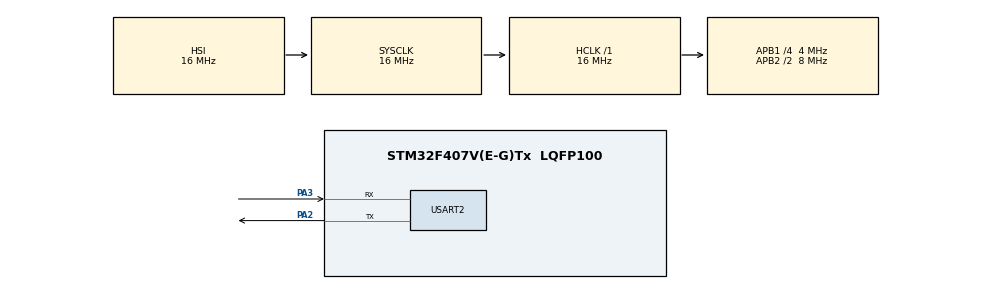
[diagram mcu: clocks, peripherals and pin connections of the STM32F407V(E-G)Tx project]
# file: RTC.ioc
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Mcu.Family=STM32F4
Mcu.Name=STM32F407V(E-G)Tx
Mcu.Package=LQFP100
NVIC.PriorityGroup=NVIC_PRIORITYGROUP_0
NVIC.USART2_IRQn=true\:0\:0\:false\:false\:true\:true\:true\:true
PA2.Mode=Asynchronous
PA2.Signal=USART2_TX
PA3.Mode=Asynchronous
PA3.Signal=USART2_RX
ProjectManager.HeapSize=0x200
ProjectManager.StackSize=0x400
ProjectManager.TargetToolchain=STM32CubeIDE
RCC.48MHZClocksFreq_Value=14285714.285714285
RCC.AHBFreq_Value=16000000
RCC.APB1CLKDivider=RCC_HCLK_DIV4
RCC.APB1Freq_Value=4000000
RCC.APB1TimFreq_Value=8000000
RCC.APB2CLKDivider=RCC_HCLK_DIV2
RCC.APB2Freq_Value=8000000
RCC.APB2TimFreq_Value=16000000
RCC.CortexFreq_Value=16000000
RCC.HCLKFreq_Value=16000000
RCC.HSE_VALUE=8000000
RCC.HSI_VALUE=16000000
RCC.LSE_VALUE=32768
RCC.PLLM=8
RCC.PLLN=50
RCC.PLLP=RCC_PLLP_DIV4
RCC.PLLQ=7
RCC.SYSCLKFreq_VALUE=16000000
RCC.VCOOutputFreq_Value=100000000
USART2.VirtualMode=VM_ASYNC
VP_RTC_VS_RTC_Activate.Mode=RTC_Enabled
VP_RTC_VS_RTC_Calendar.Mode=RTC_Calendar
board=STM32F407G-DISC1

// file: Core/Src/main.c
/* USER CODE BEGIN Header */
/**
  ******************************************************************************
  * @file           : main.c
  * @brief          : Main program body
  ******************************************************************************
  * @attention
  *
  * Copyright (c) 2025 STMicroelectronics.
  * All rights reserved.
  *
  * This software is licensed under terms that can be found in the LICENSE file
  * in the root directory of this software component.
  * If no LICENSE file comes with this software, it is provided AS-IS.
  *
  ******************************************************************************
  */
/* USER CODE END Header */
#include "main.h"

/* USER CODE BEGIN Includes */
#include "stm32f4xx_hal.h"
#include<stdio.h>
#include <string.h>

/* USER CODE END Includes */

RTC_HandleTypeDef hrtc;

UART_HandleTypeDef huart2;

/* USER CODE BEGIN PV */
int __io_putchar(int ch) {
    HAL_UART_Transmit(&huart2, (uint8_t *)&ch, 1, HAL_MAX_DELAY);
    return ch;
}

/* USER CODE END PV */

void SystemClock_Config(void);
static void MX_GPIO_Init(void);
static void MX_RTC_Init(void);
static void MX_USART2_UART_Init(void);

int main(void)
{

  /* MCU Configuration--------------------------------------------------------*/

  /* Reset of all peripherals, Initializes the Flash interface and the Systick. */
  HAL_Init();

  /* Configure the system clock */
  SystemClock_Config();

  /* Initialize all configured peripherals */
  MX_GPIO_Init();
  MX_RTC_Init();
  MX_USART2_UART_Init();
  /* USER CODE BEGIN 2 */

  RTC_TimeTypeDef sTime;
  RTC_DateTypeDef sDate;

  /* USER CODE END 2 */

  /* Infinite loop */
  while (1)
  {
	  HAL_RTC_GetTime(&hrtc, &sTime, RTC_FORMAT_BIN);
	          HAL_RTC_GetDate(&hrtc, &sDate, RTC_FORMAT_BIN);

	          printf("%02d:%02d:%02d\r\n", sTime.Hours, sTime.Minutes, sTime.Seconds);

	          HAL_Delay(1000);

  }
}

void SystemClock_Config(void)
{
  RCC_OscInitTypeDef RCC_OscInitStruct = {0};
  RCC_ClkInitTypeDef RCC_ClkInitStruct = {0};

  /** Configure the main internal regulator output voltage
  */
  __HAL_RCC_PWR_CLK_ENABLE();
  __HAL_PWR_VOLTAGESCALING_CONFIG(PWR_REGULATOR_VOLTAGE_SCALE1);

  /** Initializes the RCC Oscillators according to the specified parameters
  * in the RCC_OscInitTypeDef structure.
  */
  RCC_OscInitStruct.OscillatorType = RCC_OSCILLATORTYPE_HSI|RCC_OSCILLATORTYPE_LSI;
  RCC_OscInitStruct.HSIState = RCC_HSI_ON;
  RCC_OscInitStruct.HSICalibrationValue = RCC_HSICALIBRATION_DEFAULT;
  RCC_OscInitStruct.LSIState = RCC_LSI_ON;
  RCC_OscInitStruct.PLL.PLLState = RCC_PLL_NONE;
  if (HAL_RCC_OscConfig(&RCC_OscInitStruct) != HAL_OK)
  {
    Error_Handler();
  }

  /** Initializes the CPU, AHB and APB buses clocks
  */
  RCC_ClkInitStruct.ClockType = RCC_CLOCKTYPE_HCLK|RCC_CLOCKTYPE_SYSCLK
                              |RCC_CLOCKTYPE_PCLK1|RCC_CLOCKTYPE_PCLK2;
  RCC_ClkInitStruct.SYSCLKSource = RCC_SYSCLKSOURCE_HSI;
  RCC_ClkInitStruct.AHBCLKDivider = RCC_SYSCLK_DIV1;
  RCC_ClkInitStruct.APB1CLKDivider = RCC_HCLK_DIV4;
  RCC_ClkInitStruct.APB2CLKDivider = RCC_HCLK_DIV2;

  if (HAL_RCC_ClockConfig(&RCC_ClkInitStruct, FLASH_LATENCY_0) != HAL_OK)
  {
    Error_Handler();
  }
}

static void MX_RTC_Init(void)
{

  RTC_TimeTypeDef sTime = {0};
  RTC_DateTypeDef sDate = {0};

  /** Initialize RTC Only
  */
  hrtc.Instance = RTC;
  hrtc.Init.HourFormat = RTC_HOURFORMAT_24;
  hrtc.Init.AsynchPrediv = 127;
  hrtc.Init.SynchPrediv = 255;
  hrtc.Init.OutPut = RTC_OUTPUT_DISABLE;
  hrtc.Init.OutPutPolarity = RTC_OUTPUT_POLARITY_HIGH;
  hrtc.Init.OutPutType = RTC_OUTPUT_TYPE_OPENDRAIN;
  if (HAL_RTC_Init(&hrtc) != HAL_OK)
  {
    Error_Handler();
  }

  /** Initialize RTC and set the Time and Date
  */
  sTime.Hours = 0x0;
  sTime.Minutes = 0x0;
  sTime.Seconds = 0x0;
  sTime.DayLightSaving = RTC_DAYLIGHTSAVING_NONE;
  sTime.StoreOperation = RTC_STOREOPERATION_RESET;
  if (HAL_RTC_SetTime(&hrtc, &sTime, RTC_FORMAT_BCD) != HAL_OK)
  {
    Error_Handler();
  }
  sDate.WeekDay = RTC_WEEKDAY_MONDAY;
  sDate.Month = RTC_MONTH_JANUARY;
  sDate.Date = 0x1;
  sDate.Year = 0x0;

  if (HAL_RTC_SetDate(&hrtc, &sDate, RTC_FORMAT_BCD) != HAL_OK)
  {
    Error_Handler();
  }

}

static void MX_USART2_UART_Init(void)
{

  huart2.Instance = USART2;
  huart2.Init.BaudRate = 115200;
  huart2.Init.WordLength = UART_WORDLENGTH_8B;
  huart2.Init.StopBits = UART_STOPBITS_1;
  huart2.Init.Parity = UART_PARITY_NONE;
  huart2.Init.Mode = UART_MODE_TX_RX;
  huart2.Init.HwFlowCtl = UART_HWCONTROL_NONE;
  huart2.Init.OverSampling = UART_OVERSAMPLING_16;
  if (HAL_UART_Init(&huart2) != HAL_OK)
  {
    Error_Handler();
  }

}

static void MX_GPIO_Init(void)
{

  /* GPIO Ports Clock Enable */
  __HAL_RCC_GPIOA_CLK_ENABLE();

}

void Error_Handler(void)
{
  __disable_irq();
  while (1)
  {
  }
}
